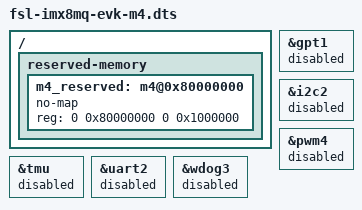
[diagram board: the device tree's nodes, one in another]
/*
 * Copyright 2017 NXP
 *
 * This program is free software; you can redistribute it and/or
 * modify it under the terms of the GNU General Public License
 * as published by the Free Software Foundation; either version 2
 * of the License, or (at your option) any later version.
 *
 * This program is distributed in the hope that it will be useful,
 * but WITHOUT ANY WARRANTY; without even the implied warranty of
 * MERCHANTABILITY or FITNESS FOR A PARTICULAR PURPOSE.  See the
 * GNU General Public License for more details.
 */

#include "fsl-imx8mq-evk.dts"

/ {
	reserved-memory {
		#address-cells = <2>;
		#size-cells = <2>;
		ranges;

		m4_reserved: m4@0x80000000 {
			no-map;
			reg = <0 0x80000000 0 0x1000000>;
		};

	};
};

&gpt1 {
	status = "disabled";
};

&i2c2 {
	status = "disabled";
};

&pwm4 {
	status = "disabled";
};

&tmu {
	status = "disabled";
};

&uart2 {
	status = "disabled";
};

&wdog3{
	status = "disabled";
};
